# A31M22x register map
Vendor: ABOV Semiconductor Co., Ltd.; File version: 1.0
CPU: CM0PLUS r0p1, little endian, no MPU, no FPU, VTOR, 2 interrupt priority bits
Registers are 32-bit, read-write, reset 0x0 unless marked. A register's access mark holds for its fields unless they carry their own. Offsets are from the block's base; [hi:lo] are bit positions; {n}, {i} and the like mark numbered series; 'fields as' and 'values as' point back to an identical list.

## ADC — 12-BIT A/D CONVERTER
Base 0x42002000
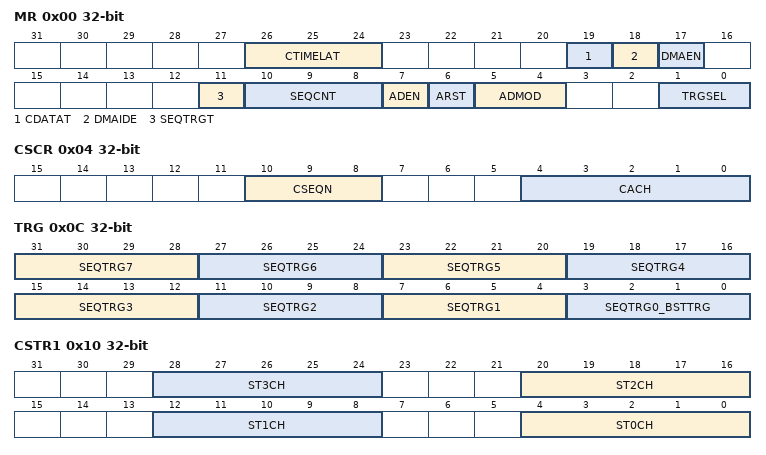
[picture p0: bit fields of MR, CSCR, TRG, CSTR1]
0x00 MR — ADC Mode Register
  [26:24] CTIMELAT — conversion_time_latency_cycle_param
  [19] CDATAT — Conversion data align sel
  [18] DMAIDE — Whether DMA contains inject data
  [17] DMAEN — DMA Enable Bit (only ADCEN=1)
    0=Disable (DMA Disable); 1=Enable (DMA Enable)
  [11] SEQTRGT — Sequential Trigger Pending Type
  [10:8] SEQCNT — Number of conversion in a sequence
    0=Single Mode; {v}={v+1} Sequence ADC (v=1..7)
  [7] ADEN — ADC Enable Bit
    0=Disable ADC; 1=Enable ADC
  [6] ARST — When sequence is over, restart control bit
    0=STOP (after ending, STOP); 1=RESTART (After ending, restart)
  [5:4] ADMOD — ADC Mode selection Bit
    0=Single_Sequencial Conversion Mode; 1=Burst Conversion Mode; 2=Multiple Conversion Mode
  [1:0] TRGSEL — Trigger selection Bit
    0=Soft_TRG (Software Trigger Only); 1=TIMER (TIMER event trigger); 2=MPWM (MPWM Event Trigger)
0x04 CSCR — ADC Current Sequence_Channel Register
  [10:8] CSEQN — Current Sequence Number
    {v}=Sequence{v} (Current Sequence {v}) (v=0..7)
  [4:0] CACH ro — Current Active Channel
    {v}=CH{v} (ADC Channel active is {v}) (v=0..19)
0x08 CCR reset 0x80 — ADC Clock Control Register
  [14:8] CLKDIV — ADC Clock Divider value bit, ADC CLK = ADC Input Clock / CLKDIV (CLKDIV=1 ADC Stop, CLKDIV=0 ADC Input Clock)
0x0C TRG — ADC Trigger Selection Register
  [all] fields
    {v}=Source {v} (v=0..7); 15=Source 15
  [4n+3:4n] SEQTRG{n} (n=1..7) — Sequence Trigger Source {n+1}th
  [3:0] SEQTRG0_BSTTRG — Sequence Trigger Source 1th, Burst Conversion Trigger Source
0x10 CSTR1 — ADC channel sampling time register 1
  [8n+4:8n] ST{n}CH (n=0..3) — {n+1}th Conversion Sequence Channel sampling time
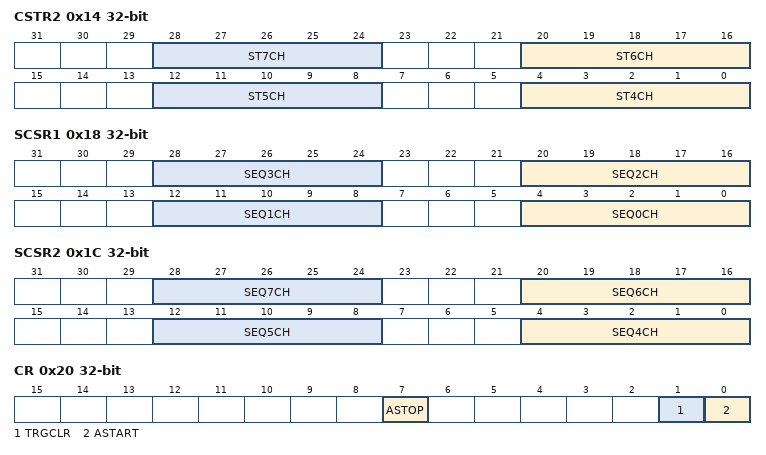
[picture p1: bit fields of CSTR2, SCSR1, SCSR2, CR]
0x14 CSTR2 — ADC channel sampling time register 2
  [8n-28:8n-32] ST{n}CH (n=4..7) — {n+1}th Conversion Sequence Channel sampling time
0x18 SCSR1 — ADC Channel selection Register 1
  [8n+4:8n] SEQ{n}CH (n=0..3) — Conversion Sequence Channel selection {n+1}th
0x1C SCSR2 — ADC Channel selection Register 2
  [8n-28:8n-32] SEQ{n}CH (n=4..7) — Conversion Sequence Channel selection {n+1}th
0x20 CR — ADC Control Register
  [7] ASTOP wo — ADC STOP bit
  [1] TRGCLR — ADC all trigger flags cleared option (previous ADC operation)
  [0] ASTART — ADC START Bit
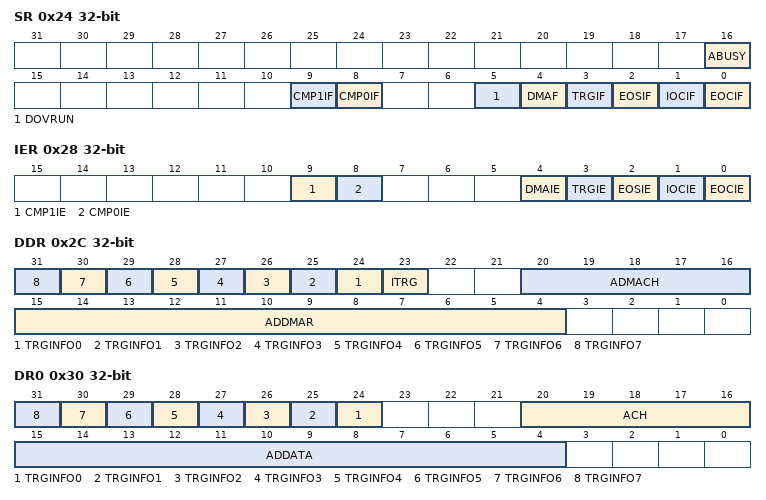
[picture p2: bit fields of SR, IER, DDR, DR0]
0x24 SR (reset mask 0xFF) — ADC Status Register
  [16] ABUSY ro — ADC busy status
  [9] CMP1IF — Compare 1 Interrupt Flag Bit
  [8] CMP0IF — Compare 0 Interrupt Flag Bit
  [5] DOVRUN ro — DMA Overrun Flag
  [4] DMAF ro — DMA Done Received Flag (DMA transfer is completed)
  [3] TRGIF — ADC Trigger Interrupt Flag (Write '1' to clear flag)
  [2] EOSIF — Sequence End Interrupt Flag (Write '1' to clear flag)
  [1] IOCIF — Inject Conversion End Interrupt Flag
  [0] EOCIF — Sequence Conversion End Interrupt Flag (Write '1' to clear flag)
0x28 IER (reset mask 0xFF) — ADC Interrupt Enable Register
  [9] CMP1IE — Compare 1 Interrupt Enable
    0=Disable compare 1 interrupt; 1=Enable compare 1 interrupt
  [8] CMP0IE — Compare 0 Interrupt Enable
    0=Disable compare 0 interrupt; 1=Enable compare 0 interrupt
  [4] DMAIE — DMA Done Interrupt Enable
    0=Disable (DMA Interrupt Disable); 1=Enable (DMA Interrupt Enable)
  [3] TRGIE — ADC Trigger Conversion Interrupt Enable
    0=Disable (ADC Trigger Conversion Interrupt Disable); 1=Enable (ADC Trigger Conversion Interrupt Enable)
  [2] EOSIE — ADC Sequence Conversion Interrupt Enable
    0=Disable (ADC Sequence Conversion Interrupt Disable); 1=Enable (ADC Sequence Conversion Interrupt Enable)
  [1] IOCIE — Inject Conversion End Interrupt Enable
    0=Disable (Inject Conversion End Interrupt Disable); 1=Enable (Inject Conversion End Interrupt Enable)
  [0] EOCIE — ADC Single Conversion Interrupt Enable
    0=Disable (ADC Single Conversion Interrupt Disable); 1=Enable (ADC Single Conversion Interrupt Enable)
0x2C DDR ro — ADC DMA Data Register
  [n+24] TRGINFO{n} (n=0..7) — ADC Trigger Information
  [23] ITRG — Injected mode trigger information
  [20:16] ADMACH — ADC Data Channel Indicator
  [15:4] ADDMAR — ADC Conversion Result Data (12-bit)
0x30 DR0 — ADC Data Register0
  [n+24] TRGINFO{n} ro (n=0..7) — ADC Trigger Information
  [20:16] ACH ro — ADC Channel Information
  [15:4] ADDATA ro — ADC Channel Data (12-bit)
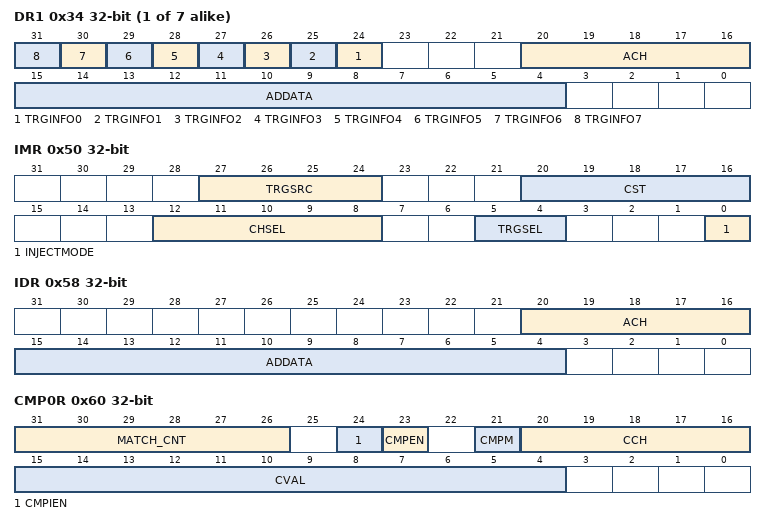
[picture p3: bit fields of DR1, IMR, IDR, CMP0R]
{0x30+4i} DR{i} (i=1..7) — ADC Sequence Data Register{i}
  fields as DR0
0x50 IMR — ADC Inject mode Register
  [27:24] TRGSRC — Trigger source selection bit
  [20:16] CST — channel samplimg time bit
  [12:8] CHSEL — channel selection
  [5:4] TRGSEL — Trigger selection bit
  [0] INJECTMODE — Inject mode enable bit
0x54 ICR — ADC Inject control Register
  [0] ASTART — ADC START Bit
0x58 IDR ro — ADC Inject Data Register
  [20:16] ACH — ADC Channel Information
  [15:4] ADDATA — ADC Input Data
0x60 CMP0R — ADC Channel Comparison 0 Register
  [31:26] MATCH_CNT — ADC Compare Match count
  [24] CMPIEN — Compare Interrupt Enable Bit
    0=Disable compare interrupt; 1=Enable Compare interrupt
  [23] CMPEN — Compare Enable Bit
    0=Disable compare; 1=Enable compare
  [21] CMPM — ADC Compare Mode Bit
    0=HIGHER (If ADC value is higher than CVAL value, compare output is high); 1=LOWER (If the ADC value is lower than the CVAL value, compare output is high)
  [20:16] CCH — Compare Channel
    {v}=CH{v} (ADC Channel {v}) (v=0..19)
  [15:4] CVAL — Compare Value
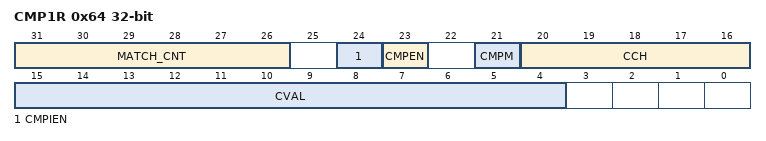
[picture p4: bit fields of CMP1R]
0x64 CMP1R — ADC Channel Comparison 1 Register
  fields as CMP0R
